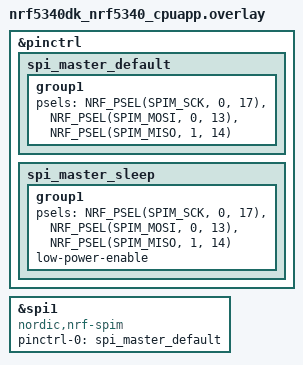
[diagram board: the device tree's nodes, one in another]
&pinctrl {
    spi_master_default: spi_master_default {
		group1 {
			psels = <NRF_PSEL(SPIM_SCK, 0, 17)>,
					<NRF_PSEL(SPIM_MOSI, 0, 13)>,
					<NRF_PSEL(SPIM_MISO, 1, 14)>;
		};
	};

	spi_master_sleep: spi_master_sleep {
		group1 {
			psels = <NRF_PSEL(SPIM_SCK, 0, 17)>,
					<NRF_PSEL(SPIM_MOSI, 0, 13)>,
					<NRF_PSEL(SPIM_MISO, 1, 14)>;
			low-power-enable;
		};
	};

};

&spi1 {
    status = "okay";
    compatible = "nordic,nrf-spim";
    pinctrl-0 = <&spi_master_default>;
};
